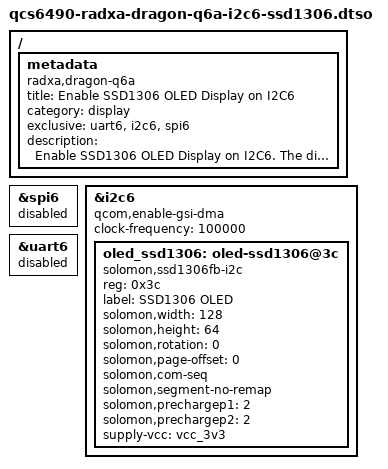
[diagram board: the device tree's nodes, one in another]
// SPDX-License-Identifier: BSD-3-Clause
/*
 * Copyright (c) 2025 Radxa Computer (Shenzhen) Co., Ltd.
 */

/dts-v1/;
/plugin/;

/ {
	metadata {
		title = "Enable SSD1306 OLED Display on I2C6";
		compatible = "radxa,dragon-q6a";
		category = "display";
		exclusive = "uart6", "i2c6", "spi6";
		description = "Enable SSD1306 OLED Display on I2C6.

The display resolution is fixed at 128x64.
On Radxa Dragon Q6A, this is pin 5(scl), 3(sda).";
	};
};

&spi6 {
	status = "disabled";
};

&i2c6 {
	qcom,enable-gsi-dma;
	status = "okay";

	clock-frequency = <100000>;

    oled_ssd1306: oled-ssd1306@3c {
        compatible = "solomon,ssd1306fb-i2c";
        reg = <0x3c>;
        label = "SSD1306 OLED";
        solomon,width = <128>;
        solomon,height = <64>;
        solomon,rotation = <0>;
        solomon,page-offset = <0>;
        solomon,com-seq;
        solomon,segment-no-remap;
        solomon,prechargep1 = <2>;
        solomon,prechargep2 = <2>;
        supply-vcc = <&vcc_3v3>;
    };
};

&uart6 {
	status = "disabled";
};
